# ATSAM3X4C device description
Architecture: CORTEX-M3; Family: SAM3; Series: SAM3XA
Registers are 32-bit, read-write, no defined reset value unless marked. A register's access mark holds for its fields unless they carry their own. Offsets are from the block's base; [hi:lo] are bit positions; {n}, {i} and the like mark numbered series; 'fields as' and 'values as' point back to an identical list.

## CHIPID — Chip Identifier
Instances: CHIPID 0x400E0940
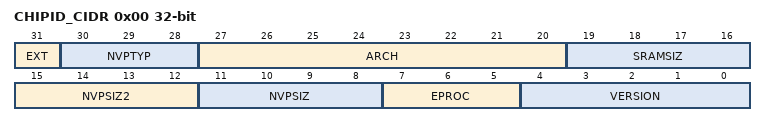
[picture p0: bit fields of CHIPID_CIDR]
0x00 CHIPID_CIDR ro — Chip ID Register
  [31] EXT — Extension Flag
  [30:28] NVPTYP — Nonvolatile Program Memory Type
    0=ROM; 1=ROMLESS (ROMless or on-chip Flash); 2=FLASH (Embedded Flash Memory); 3=ROM_FLASH (ROM and Embedded Flash Memory- NVPSIZ is ROM size- NVPSIZ2 is Flash size); 4=SRAM (SRAM emulating ROM)
  [27:20] ARCH — Architecture Identifier
    131=SAM3AxC (100-pin version); 132=SAM3XxC (100-pin version); 133=SAM3XxE (144-pin version); 134=SAM3XxG (208/217-pin version)
  [19:16] SRAMSIZ — Internal SRAM Size
    0=_48K (48 Kbytes); 1=_192K (192 Kbytes); 2=_2K (2 Kbytes); 3=_6K (6 Kbytes); 4=_24K (24 Kbytes); 5=_4K (4 Kbytes); 6=_80K (80 Kbytes); 7=_160K (160 Kbytes); 8=_8K (8 Kbytes); 9=_16K (16 Kbytes); 10=_32K (32 Kbytes); 11=_64K (64 Kbytes); 12=_128K (128 Kbytes); 13=_256K (256 Kbytes); 14=_96K (96 Kbytes); 15=_512K (512 Kbytes)
  [15:12] NVPSIZ2 — Second Nonvolatile Program Memory Size
    0=NONE; 1=_8K (8 Kbytes); 2=_16K (16 Kbytes); 3=_32K (32 Kbytes); 5=_64K (64 Kbytes); 7=_128K (128 Kbytes); 9=_256K (256 Kbytes); 10=_512K (512 Kbytes); 12=_1024K (1024 Kbytes); 14=_2048K (2048 Kbytes)
  [11:8] NVPSIZ — Nonvolatile Program Memory Size
    values as NVPSIZ2
  [7:5] EPROC — Embedded Processor
    1=ARM946ES; 2=ARM7TDMI; 3=CM3 (Cortex-M3); 4=ARM920T; 5=ARM926EJS; 6=CA5 (Cortex-A5); 7=CM4 (Cortex-M4)
  [4:0] VERSION — Version of the Device
0x04 CHIPID_EXID ro — Chip ID Extension Register
  [31:0] EXID — Chip ID Extension

## EFC — Embedded Flash Controller
Instances: EFC0 0x400E0A00, EFC1 0x400E0C00
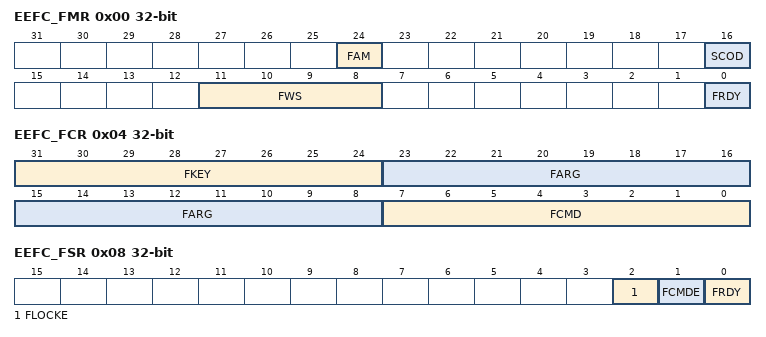
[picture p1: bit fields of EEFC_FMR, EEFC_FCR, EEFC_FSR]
0x00 EEFC_FMR — EEFC Flash Mode Register
  [24] FAM — Flash Access Mode
  [16] SCOD — Sequential Code Optimization Disable
  [11:8] FWS — Flash Wait State
  [0] FRDY — Ready Interrupt Enable
0x04 EEFC_FCR wo — EEFC Flash Command Register
  [31:24] FKEY — Flash Writing Protection Key
    90=PASSWD (The 0x5A value enables the command defined by the bits of the register. If the field is written with a different value, the write is not performed and no action is started.)
  [23:8] FARG — Flash Command Argument
  [7:0] FCMD — Flash Command
    0=GETD (Get Flash Descriptor); 1=WP (Write page); 2=WPL (Write page and lock); 3=EWP (Erase page and write page); 4=EWPL (Erase page and write page then lock); 5=EA (Erase all); 8=SLB (Set Lock Bit); 9=CLB (Clear Lock Bit); 10=GLB (Get Lock Bit); 11=SGPB (Set GPNVM Bit); 12=CGPB (Clear GPNVM Bit); 13=GGPB (Get GPNVM Bit); 14=STUI (Start Read Unique Identifier); 15=SPUI (Stop Read Unique Identifier); 16=GCALB (Get CALIB Bit)
0x08 EEFC_FSR ro — EEFC Flash Status Register
  [2] FLOCKE — Flash Lock Error Status
  [1] FCMDE — Flash Command Error Status
  [0] FRDY — Flash Ready Status
0x0C EEFC_FRR ro — EEFC Flash Result Register
  [31:0] FVALUE — Flash Result Value

## GPBR — General Purpose Backup Registers
Instances: GPBR 0x400E1A90
{0x0+4i} SYS_GPBR{i} (i=0..7) — General Purpose Backup Register {i}
  [31:0] GPBR_VALUE — Value of GPBR x

## MATRIX — AHB Bus Matrix
Instances: MATRIX 0x400E0400
{0x0+4i} MATRIX_MCFG{i} (i=0..5) — Master Configuration Register {i}
  [2:0] ULBT — Undefined Length Burst Type
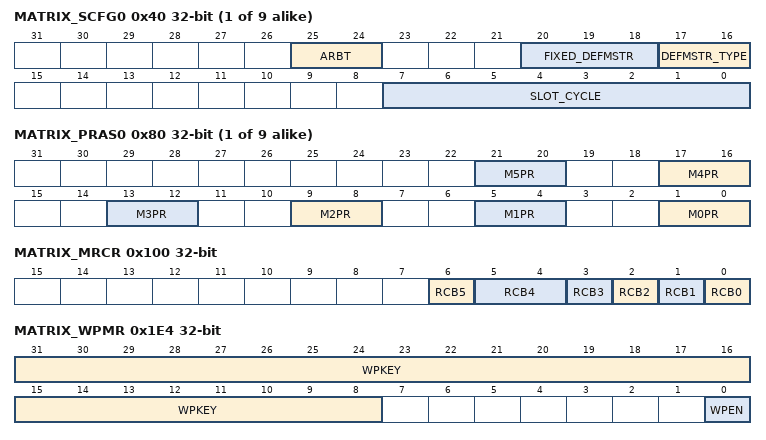
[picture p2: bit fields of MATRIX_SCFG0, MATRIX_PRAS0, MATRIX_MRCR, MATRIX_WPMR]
{0x40+4i} MATRIX_SCFG{i} (i=0..8) — Slave Configuration Register {i}
  [25:24] ARBT — Arbitration Type
  [20:18] FIXED_DEFMSTR — Fixed Default Master
  [17:16] DEFMSTR_TYPE — Default Master Type
  [7:0] SLOT_CYCLE — Maximum Number of Allowed Cycles for a Burst
{0x80+8i} MATRIX_PRAS{i} (i=0..8) — Priority Register A for Slave {i}
  [4n+1:4n] M{n}PR (n=0..5) — Master {n} Priority
0x100 MATRIX_MRCR — Master Remap Control Register
  [6] RCB5 — Remap Command Bit for AHB Master 5
  [5:4] RCB4 — Remap Command Bit for AHB Master 4
  [n] RCB{n} (n=0..3) — Remap Command Bit for AHB Master {n}
0x114 CCFG_SYSIO — System I/O Configuration register
  [12] SYSIO12 — PC0 or ERASE Assignment
0x1E4 MATRIX_WPMR — Write Protect Mode Register
  [31:8] WPKEY — Write Protect KEY (Write-only)
  [0] WPEN — Write Protect ENable
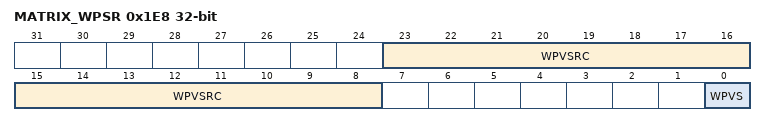
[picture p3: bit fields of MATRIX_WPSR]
0x1E8 MATRIX_WPSR ro — Write Protect Status Register
  [23:8] WPVSRC — Write Protect Violation Source
  [0] WPVS — Write Protect Violation Status

## Notices in the file
SAM Software Package License
Copyright (c) %copyright_year%, Atmel Corporation
All rights reserved.
Redistribution and use in source and binary forms, with or without
modification, are permitted provided that the following condition is met:
- Redistributions of source code must retain the above copyright notice,
this list of conditions and the disclaimer below.
Atmel's name may not be used to endorse or promote products derived from
this software without specific prior written permission.
DISCLAIMER:  THIS SOFTWARE IS PROVIDED BY ATMEL "AS IS" AND ANY EXPRESS OR
IMPLIED WARRANTIES, INCLUDING, BUT NOT LIMITED TO, THE IMPLIED WARRANTIES OF
MERCHANTABILITY, FITNESS FOR A PARTICULAR PURPOSE AND NON-INFRINGEMENT ARE
DISCLAIMED. IN NO EVENT SHALL ATMEL BE LIABLE FOR ANY DIRECT, INDIRECT,
INCIDENTAL, SPECIAL, EXEMPLARY, OR CONSEQUENTIAL DAMAGES (INCLUDING, BUT NOT
LIMITED TO, PROCUREMENT OF SUBSTITUTE GOODS OR SERVICES; LOSS OF USE, DATA,
OR PROFITS; OR BUSINESS INTERRUPTION) HOWEVER CAUSED AND ON ANY THEORY OF
LIABILITY, WHETHER IN CONTRACT, STRICT LIABILITY, OR TORT (INCLUDING
NEGLIGENCE OR OTHERWISE) ARISING IN ANY WAY OUT OF THE USE OF THIS SOFTWARE,
EVEN IF ADVISED OF THE POSSIBILITY OF SUCH DAMAGE.
